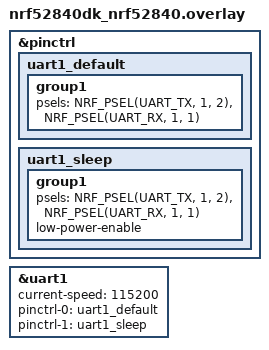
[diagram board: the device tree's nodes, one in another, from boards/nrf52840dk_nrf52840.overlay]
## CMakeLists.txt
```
cmake_minimum_required(VERSION 3.20.0)
find_package(Zephyr REQUIRED HINTS $ENV{ZEPHYR_BASE})

project(firmware)

# -----------------------------------------------------------------------------
# nanopb — generate C sources from Meshtastic .proto files
#
# firmware/proto is a symlink to the Meshtastic protobuf repo:
#   CPS-RTC/Decentralized_LoRa/nordic/proto
# (same set used by the reference project; .options files are co-located)
# -----------------------------------------------------------------------------
list(APPEND CMAKE_MODULE_PATH ${ZEPHYR_BASE}/modules/nanopb)
include(nanopb)

set(MTS_PROTO ${CMAKE_CURRENT_SOURCE_DIR}/proto)
set(NANOPB_IMPORT_DIRS ${MTS_PROTO})
set(NANOPB_GENERATE_CPP_STANDALONE OFF)

nanopb_generate_cpp(proto_srcs proto_hdrs RELPATH ${MTS_PROTO}
    ${MTS_PROTO}/meshtastic/mesh.proto
    ${MTS_PROTO}/meshtastic/portnums.proto
    ${MTS_PROTO}/meshtastic/channel.proto
    ${MTS_PROTO}/meshtastic/config.proto
    ${MTS_PROTO}/meshtastic/device_ui.proto
    ${MTS_PROTO}/meshtastic/module_config.proto
    ${MTS_PROTO}/meshtastic/atak.proto
    ${MTS_PROTO}/meshtastic/telemetry.proto
    ${MTS_PROTO}/meshtastic/xmodem.proto
)

# -----------------------------------------------------------------------------
# Application sources
# -----------------------------------------------------------------------------
target_sources(app PRIVATE
    ${proto_srcs}
    ${proto_hdrs}
    src/main.c
    src/ble_gatt.c
    src/uart_meshtastic.c
    src/proto_handler.c
    src/router.c
    src/proxy_protocol.c
    src/config_cache.c
    src/upstream_session.c
)

# nanopb generates headers into the build directory
target_include_directories(app PRIVATE ${CMAKE_CURRENT_BINARY_DIR})
```

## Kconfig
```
# =============================================================================
# Meshtastic BLE Proxy — application Kconfig
#
# Providing an app-level Kconfig makes this file the Kconfig *root* for the
# build, so it MUST source the Zephyr Kconfig tree at the end (otherwise all
# CONFIG_BT_*, CONFIG_LOG_*, etc. disappear).
# =============================================================================

menu "Meshtastic BLE Proxy"

config MESHTASTIC_ROUTE_TRACE
	bool "Enable ROUTE message-path tracing logs"
	default n
	help
	  Emit per-hop "ROUTE UP/DN ..." INFO logs that trace a message across
	  the proxy (BLE <-> UART): the phone write, the routing decision, the
	  UART TX/RX, and the per-phone serve. Useful for debugging the
	  end-to-end path during bring-up and testing.

	  This adds processing time on the packet hot path. When disabled, the
	  trace calls compile out entirely (zero overhead) — leave it off for
	  production builds and enable it only while debugging.

config MESHTASTIC_ROUTE_TRACE_PAYLOAD
	bool "Also hexdump packet payloads in ROUTE traces"
	depends on MESHTASTIC_ROUTE_TRACE
	default n
	help
	  In addition to the ROUTE path logs, hexdump the raw ToRadio bytes
	  (uplink) and the decoded FromRadio Data.payload (downlink). The
	  hexdump's ASCII column reveals text-message content. More verbose and
	  slower — enable only when you need to see the actual message bytes.

endmenu

source "Kconfig.zephyr"
```

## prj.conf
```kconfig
# =============================================================================
# Meshtastic BLE Proxy — nRF52840
# =============================================================================

# -----------------------------------------------------------------------------
# Bluetooth — Peripheral, up to 6 simultaneous connections
# -----------------------------------------------------------------------------
CONFIG_BT=y
CONFIG_BT_PERIPHERAL=y
CONFIG_BT_MAX_CONN=6
# ACL TX buffer pool: at least one per connection to avoid head-of-line blocking
CONFIG_BT_BUF_ACL_TX_COUNT=8

# -----------------------------------------------------------------------------
# Connection parameters — wide range so Android's param update is accepted
# Android sends LL_CONNECTION_PARAM_REQ at ~1-3s; if outside preferred range
# Zephyr rejects it and Android disconnects with 0x13.
# Units: 1.25 ms per interval unit, 10 ms per timeout unit.
# -----------------------------------------------------------------------------
CONFIG_BT_PERIPHERAL_PREF_MIN_INT=6
CONFIG_BT_PERIPHERAL_PREF_MAX_INT=100
CONFIG_BT_PERIPHERAL_PREF_LATENCY=0
CONFIG_BT_PERIPHERAL_PREF_TIMEOUT=400
# Must match BLE_NAME_PATTERN: ^.*_([0-9a-fA-F]{4})$
# Last 4 chars = hex suffix (ideally derived from MAC). Change before flashing.
CONFIG_BT_DEVICE_NAME="Meshtastic_CA1E"

# -----------------------------------------------------------------------------
# nanopb — protobuf decode for FromRadio routing (Phase 3)
# -----------------------------------------------------------------------------
CONFIG_NANOPB=y
CONFIG_RING_BUFFER=y

# ATT: larger MTU so FromRadio packets fit in a single read (no long-read needed)
CONFIG_BT_L2CAP_TX_MTU=251
CONFIG_BT_BUF_ACL_RX_SIZE=256
CONFIG_BT_BUF_ACL_TX_SIZE=256

# Static GATT table (BT_GATT_SERVICE_DEFINE)
CONFIG_BT_GATT_DYNAMIC_DB=n

# SMP: allow Android "Just Works" bonding.
# Android always sends Pairing Request with auth_req bonding flag set.
# CONFIG_BT_BONDABLE=n causes Zephyr to respond with bonding=0, which
# Android rejects after 3s (0x13). Allowing bonding with MAX_PAIRED=6
# lets Android complete the SC pairing and stay connected.
# Bonds are RAM-only (no CONFIG_BT_SETTINGS) — lost on reboot, which is
# fine: Android re-pairs on next connect with "Just Works".
CONFIG_BT_SMP=y
CONFIG_BT_MAX_PAIRED=6
CONFIG_BT_SMP_SC_ONLY=n
CONFIG_BT_SMP_SC_PAIR_ONLY=n

# -----------------------------------------------------------------------------
# GPIO — blinky activity LEDs (BLE read/write events)
# -----------------------------------------------------------------------------
CONFIG_GPIO=y

# -----------------------------------------------------------------------------
# UART — Meshtastic serial link on UART1 (P1.01 RX / P1.02 TX)
# -----------------------------------------------------------------------------
CONFIG_SERIAL=y
CONFIG_UART_ASYNC_API=y
# Hardware-async RX: a dedicated TIMER (via PPI) counts received bytes so the
# async driver can flush a PARTIAL DMA buffer on the UART_RX_TIMEOUT_US idle
# gap — not only when the 256-byte buffer fills. Without this, a lone FromRadio
# frame stalled in the DMA buffer until unrelated later traffic topped it up,
# coupling inbound delivery to outbound sends. TIMER0 is owned by the BLE
# controller; TIMER2 is free.
CONFIG_UART_1_NRF_HW_ASYNC=y
CONFIG_UART_1_NRF_HW_ASYNC_TIMER=2

# -----------------------------------------------------------------------------
# Logging (UART0 / JLink — independent of Meshtastic UART1)
# -----------------------------------------------------------------------------
CONFIG_LOG=y
CONFIG_LOG_DEFAULT_LEVEL=3
# Larger log buffer: the bonding/config phase bursts a lot of log traffic; a
# small buffer makes the log core drop its own lines ("--- N messages dropped ---").
CONFIG_LOG_BUFFER_SIZE=8192

# BT stack debug was only needed while chasing the 0x13 disconnect, which is now
# resolved (stable multi-phone connections). Removed: the DBG flood overran the
# log backend during bonding and caused dropped log lines. Re-enable temporarily
# if a new connection-layer issue needs tracing.
#   CONFIG_BT_CONN_LOG_LEVEL_DBG=y
#   CONFIG_BT_SMP_LOG_LEVEL_DBG=y

# -----------------------------------------------------------------------------
# Route tracing (debug) — per-hop "ROUTE UP/DN ..." logs of the message path.
# Master switch: compiles the trace calls out entirely when =n (zero overhead).
# _PAYLOAD additionally hexdumps ToRadio/FromRadio payloads (ASCII column shows
# text-message content). Turn both off for production builds.
# -----------------------------------------------------------------------------
CONFIG_MESHTASTIC_ROUTE_TRACE=y
CONFIG_MESHTASTIC_ROUTE_TRACE_PAYLOAD=y

# -----------------------------------------------------------------------------
# Memory
# -----------------------------------------------------------------------------
CONFIG_HEAP_MEM_POOL_SIZE=8192
CONFIG_MAIN_STACK_SIZE=4096
CONFIG_SYSTEM_WORKQUEUE_STACK_SIZE=2048
```

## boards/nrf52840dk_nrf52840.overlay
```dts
/*
 * Board overlay — nRF52840 DK
 *
 * UART1: Meshtastic serial link
 *   P1.02 → TX (to Meshtastic RX)
 *   P1.01 → RX (from Meshtastic TX)
 *
 * UART0 (P0.06/P0.08) stays untouched — used by Zephyr shell/logging via JLink.
 */

&pinctrl {
    uart1_default: uart1_default {
        group1 {
            psels = <NRF_PSEL(UART_TX, 1, 2)>,   /* P1.02 */
                    <NRF_PSEL(UART_RX, 1, 1)>;    /* P1.01 */
        };
    };

    uart1_sleep: uart1_sleep {
        group1 {
            psels = <NRF_PSEL(UART_TX, 1, 2)>,
                    <NRF_PSEL(UART_RX, 1, 1)>;
            low-power-enable;
        };
    };
};

&uart1 {
    status = "okay";
    current-speed = <115200>;
    pinctrl-0 = <&uart1_default>;
    pinctrl-1 = <&uart1_sleep>;
    pinctrl-names = "default", "sleep";
};
```

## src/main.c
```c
#include <zephyr/kernel.h>
#include <zephyr/bluetooth/bluetooth.h>
#include <zephyr/logging/log.h>
#include <zephyr/sys/byteorder.h>
#include <inttypes.h>
#include "ble_gatt.h"
#include "uart_meshtastic.h"
#include "proto_handler.h"
#include "router.h"
#include "upstream_session.h"
#include "proxy_protocol.h"
#include "route_trace.h"

LOG_MODULE_REGISTER(main, LOG_LEVEL_INF);

/*
 * Called (system work-queue context) when the UART driver has assembled a
 * complete FromRadio frame from the Meshtastic node.
 *
 * Flow:
 *   1. Decode the protobuf (nanopb) to extract routing fields.
 *   2. Dispatch raw bytes to the correct BLE connection(s) via the router.
 *
 * On decode failure the raw bytes are still broadcast so no packet is dropped.
 */
static void on_fromradio_uart(const uint8_t *payload, uint16_t len)
{
    struct fromradio_info info;

    if (proto_decode_fromradio(payload, len, &info) != 0) {
        /* Decode failed (malformed frame?). Broadcast raw as fallback. */
        LOG_WRN("FromRadio decode failed — broadcasting raw (%d B)", len);
        ble_gatt_broadcast_fromradio(payload, len);
        return;
    }

    router_dispatch(payload, len, &info);
}

/*
 * Called when a phone writes a ToRadio protobuf to the GATT TORADIO
 * characteristic (per-phone config-session virtualization).
 *
 * The proxy is NO LONGER a blind passthrough:
 *   - want_config_id : served LOCALLY from the cache (replay or PENDING).
 *                      NEVER forwarded to UART — forwarding it would restart the
 *                      node's single global config session and clobber every
 *                      other phone's in-flight handshake.
 *   - heartbeat      : absorbed locally — answered with a synthesized
 *                      queueStatus for liveness; NEVER forwarded to UART. The
 *                      node's serial link is kept alive by the proxy's own
 *                      keepalive, and delivery of inbound FromRadio is driven by
 *                      the node's push (not by client ToRadio), so forwarding
 *                      heartbeats is unnecessary.
 *   - anything else  : a real packet → forwarded to the node via UART as today.
 *
 * On decode failure we forward the raw bytes best-effort (no silent drop).
 */
static void on_toradio_ble(struct bt_conn *conn, const uint8_t *data, uint16_t len)
{
    struct toradio_info ti;

    if (proto_decode_toradio(data, len, &ti) != 0) {
        /* Malformed ToRadio — forward best-effort so nothing is silently lost. */
        LOG_WRN("ToRadio decode failed (%d B) from conn %p — forwarding raw",
                len, (void *)conn);
        (void)uart_meshtastic_tx(data, len);
        return;
    }

    if (ti.has_want_config) {
        /* Serve config locally: replay if the cache is ready, else PENDING. */
        enum upstream_state st = upstream_get_state();
        if (st == UPSTREAM_CACHE_READY || st == UPSTREAM_LIVE) {
            LOG_INF("want_config nonce=%u from conn %p → replay cached burst",
                    (unsigned)ti.want_config_id, (void *)conn);
            ble_gatt_replay_cached_burst(conn, ti.want_config_id);
        } else {
            LOG_INF("want_config nonce=%u from conn %p → PENDING (cache not ready)",
                    (unsigned)ti.want_config_id, (void *)conn);
            ble_gatt_park_pending(conn, ti.want_config_id);
        }
        return;  /* NEVER forward want_config to UART. */
    }

    if (ti.has_heartbeat) {
        /* Absorbed locally: reply a synthesized queueStatus to keep the
         * phone's liveness timer alive. */
        ble_gatt_reply_queuestatus(conn);
        return;
    }
#if IS_ENABLED(CONFIG_MESHTASTIC_ROUTE_TRACE)
    /* TESTING ONLY: Assumes proxy-framed payload with 4-byte IDs. */
    if (ti.is_packet && ti.portnum == PROXY_PORTNUM && ti.payload_len >= PROXY_HEADER_SIZE) {
        ROUTE_TRACE("ROUTE UP  hdr=[%02x][0x%08" PRIx32 "][0x%08" PRIx32 "] content='%.*s'",
                    ti.payload_bytes[PROXY_OFF_VERSION],
                    sys_get_be32(&ti.payload_bytes[PROXY_OFF_SRC]),
                    sys_get_be32(&ti.payload_bytes[PROXY_OFF_DST]),
                    (int)(ti.payload_len - PROXY_HEADER_SIZE),
                    (const char *)&ti.payload_bytes[PROXY_OFF_CONTENT]);
        ROUTE_TRACE_HEXDUMP(ti.payload_bytes, ti.payload_len, "ROUTE UP payload");
    }
#endif 
    /* Real packet → forward to the node, and push the upstream keepalive out
     * the keepalive only fires after a stretch of true silence. */
    int err = uart_meshtastic_tx(data, len);
    if (err == -ENOMEM) {
        LOG_WRN("TX queue full — ToRadio from conn %p dropped", (void *)conn);
    } else if (err) {
        LOG_ERR("uart_meshtastic_tx: %d", err);
    } else {
        upstream_keepalive_reschedule();
    }
}

int main(void)
{
    int err;

    LOG_INF("=== Meshtastic BLE Proxy starting ===");

    /* 1. Init GATT service (must happen before bt_enable). */
    err = ble_gatt_init(on_toradio_ble);
    if (err) {
        LOG_ERR("ble_gatt_init: %d", err);
        return err;
    }

    /* 2. Enable Bluetooth stack. */
    err = bt_enable(NULL);
    if (err) {
        LOG_ERR("bt_enable: %d", err);
        return err;
    }
    LOG_INF("Bluetooth ready");

    /* 3. Start advertising as a Meshtastic-compatible peripheral. */
    err = ble_gatt_start_advertising();
    if (err) {
        return err;
    }

    /* 4. Init UART driver — starts DMA reception immediately.
     *    The Meshtastic node begins sending FromRadio frames once it receives
     *    the proxy's own want_config_id ToRadio (sent by upstream_session_start
     *    below), not a phone's — phones are served from the cache. */
    err = uart_meshtastic_init(on_fromradio_uart);
    if (err) {
        LOG_ERR("uart_meshtastic_init: %d", err);
        return err;
    }

    /* 5. Wire the per-phone replay callback BEFORE starting the upstream fetch,
     *    so any PENDING phone queued during FETCHING is served the instant the
     *    cache becomes ready. */
    upstream_set_serve_cb(ble_gatt_replay_cached_burst);

    /* 6. Kick off the proxy's own boot want_config: fetch the node's config
     *    burst into the cache, then go LIVE. Phones connecting before the cache
     *    is ready are parked PENDING and replayed once ready. */
    upstream_session_start();

    /* Main loop — all work runs in the system work queue and BT callbacks. */
    while (1) {
        k_sleep(K_MSEC(100));
    }

    return 0;
}
```

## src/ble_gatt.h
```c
#ifndef BLE_GATT_H
#define BLE_GATT_H

#include <stdint.h>
#include <zephyr/bluetooth/conn.h>
#include "proxy_protocol.h"

/* Max simultaneous BLE connections (phones).
 * Tied to CONFIG_BT_MAX_CONN so the app-layer slot array always matches the
 * BT stack limit. Change prj.conf (CONFIG_BT_MAX_CONN) to resize both at once. */
#define MAX_BLE_CONNECTIONS     CONFIG_BT_MAX_CONN

/* Per-connection FromRadio packet queue depth */
#define FROMRADIO_QUEUE_DEPTH   8

/* Max size of a single FromRadio protobuf packet (bytes) */
#define FROMRADIO_MAX_PKT_SIZE  512

/*
 * Per-phone config-session state.
 *
 *   CONNECTED          → just connected (CCCD not yet subscribed)
 *   AWAIT_WANT_CONFIG  → subscribed, waiting for the phone's want_config
 *   PENDING            → asked for config before the cache was ready; queued in
 *                        upstream_session and served once CACHE_READY
 *   REPLAYING          → mid burst replay (cursor walking the shared cache)
 *   ACTIVE             → burst replayed + config_complete sent; live traffic
 */
enum phone_state {
    PHONE_CONNECTED,
    PHONE_AWAIT_WANT_CONFIG,
    PHONE_PENDING,
    PHONE_REPLAYING,
    PHONE_ACTIVE,
};

/**
 * Callback fired when a connected phone writes to the TORADIO characteristic.
 *
 * @param conn  BLE connection that sent the data.
 * @param data  Raw protobuf bytes (ToRadio message, already encoded by the app).
 * @param len   Length in bytes.
 */
typedef void (*toradio_cb_t)(struct bt_conn *conn, const uint8_t *data, uint16_t len);

/** Initialize GATT service and connection tracking. Must be called before bt_enable(). */
int ble_gatt_init(toradio_cb_t cb);

/** Start BLE advertising (Meshtastic-compatible). Called at boot and after each connection. */
int ble_gatt_start_advertising(void);

/**
 * Enqueue a FromRadio packet for a specific BLE connection.
 * Triggers a FROMNUM notification to the phone.
 *
 * @return  0        success
 *         -ENOENT   connection not tracked
 *         -ENOMEM   per-connection queue full
 *         -EMSGSIZE packet exceeds FROMRADIO_MAX_PKT_SIZE
 */
int ble_gatt_enqueue_fromradio(struct bt_conn *conn, const uint8_t *data, uint16_t len);

/**
 * Enqueue a FromRadio packet for ALL currently connected BLE clients.
 * Used for config/meta variants and broadcast mesh packets.
 *
 * @return Number of connections that received the packet (0 if none connected).
 */
int ble_gatt_broadcast_fromradio(const uint8_t *data, uint16_t len);

/**
 * Return the BLE connection whose registered proxy_id matches the given id.
 * Returns NULL if no connection has registered that id.
 *
 * Used by the router to target a specific phone by its proxy identifier.
 */
struct bt_conn *ble_gatt_get_conn_by_proxy_id(const proxy_id_t *id);

/**
 * Register a proxy identifier (phone number, UUID, etc.) for a BLE connection.
 *
 * Called from the NODE_REG GATT write handler when a phone writes its 16-byte
 * identifier.  The router uses this mapping to perform targeted delivery.
 *
 * @param conn  The BLE connection registering.
 * @param id    16-byte proxy identifier written by the phone.
 * @return 0 on success, -ENOENT if connection is not tracked.
 */
int ble_gatt_register_proxy_id(struct bt_conn *conn, const proxy_id_t *id);

/*
 * Replay the boot-populated config cache to a single phone, then close the
 * burst with a synthesized FromRadio{config_complete_id = nonce} carrying THAT
 * phone's nonce (per-phone replay).
 *
 * Frames are read straight from the shared config_cache arena via a cursor and
 * enqueued one by one — the whole burst is never copied into the per-conn queue
 * as a block (avoids N× RAM duplication). On completion the phone goes ACTIVE.
 *
 * Called from on_toradio_ble (cache already ready) and registered with
 * upstream_session as the serve callback for PENDING phones.
 */
void ble_gatt_replay_cached_burst(struct bt_conn *conn, uint32_t nonce);

/*
 * Park a phone as PENDING: it asked for config before the cache was ready.
 * Records the phone's nonce and registers it with upstream_session, which
 * replays the burst (via the serve callback) once CACHE_READY.
 */
void ble_gatt_park_pending(struct bt_conn *conn, uint32_t nonce);

/*
 * Task D — reactive BLE liveness reply. Enqueue a synthesized FromRadio{
 * queueStatus} to this connection (bumps fromnum + notifies FROMNUM) in
 * response to the phone's ToRadio.heartbeat. The phone reads it as "radio
 * data", keeping its app-layer liveness timer from tripping. Absorbed locally
 * — the heartbeat is NEVER forwarded to UART. The queueStatus is encoded once
 * and reused.
 */
void ble_gatt_reply_queuestatus(struct bt_conn *conn);

#endif /* BLE_GATT_H */
```

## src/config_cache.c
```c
/*
 * config_cache.c — packed contiguous store of the node's config burst.
 *
 * Layout
 * ------
 *   s_arena[CONFIG_CACHE_ARENA_BYTES]   one byte buffer, frames packed
 *                                       back-to-back, NO per-frame padding.
 *   s_index[CONFIG_CACHE_MAX_FRAMES]    {offset, len, variant} per stored frame.
 *   s_used                              bytes consumed in the arena so far.
 *   s_count                             number of index entries used.
 *   s_ready (atomic_t)                  publish flag (see barrier note below).
 *   s_queuestatus_idx                   index of the cached queueStatus frame,
 *                                       or -1 if none was stored.
 *
 * Threading / memory model
 * ------------------------
 * NO mutexes. All writers (cache_begin / cache_add_frame / cache_mark_ready)
 * run on the single Zephyr system work queue (UART RX → upstream_session), so
 * they never race. Publication uses a Zephyr atomic_t:
 *
 *   - cache_mark_ready() does atomic_set(&s_ready, 1). atomic_set is a
 *     release-store: all prior plain writes (every arena byte, every s_index
 *     entry, s_used, s_count, s_queuestatus_idx) are visible to any thread
 *     that subsequently observes the new value of s_ready.
 *   - cache_is_ready() does atomic_get(&s_ready), an acquire-load: once it
 *     returns true, the reader is guaranteed to see the fully-written arena.
 *
 * This is the ONLY synchronization the cache relies on; it is correct even if a
 * future reader is moved off the system work queue (e.g. a BLE TX thread)
 * without adding a mutex. See config_cache.h for the full rationale.
 */

#include "config_cache.h"

#include <string.h>
#include <errno.h>
#include <zephyr/sys/atomic.h>
#include <zephyr/logging/log.h>

#include "meshtastic/mesh.pb.h"   /* meshtastic_FromRadio_queueStatus_tag */

LOG_MODULE_REGISTER(config_cache, LOG_LEVEL_INF);

static uint8_t                s_arena[CONFIG_CACHE_ARENA_BYTES];
static struct cache_frame_ref s_index[CONFIG_CACHE_MAX_FRAMES];
static uint16_t               s_used;
static uint16_t               s_count;
static atomic_t               s_ready;
static int                    s_queuestatus_idx = -1;
static int                    s_own_nodeinfo_idx = -1;  /* first node_info = OWN */

void cache_begin(void)
{
    /* Reset for a fresh burst. Clear ready FIRST so no reader can observe a
     * stale "ready" while we are mid-rewrite. */
    atomic_set(&s_ready, 0);
    s_used             = 0;
    s_count            = 0;
    s_queuestatus_idx  = -1;
    s_own_nodeinfo_idx = -1;
    LOG_INF("cache_begin: arena=%u B, max_frames=%u",
            (unsigned)CONFIG_CACHE_ARENA_BYTES,
            (unsigned)CONFIG_CACHE_MAX_FRAMES);
}

int cache_add_frame(const uint8_t *raw, uint16_t len, int variant)
{
    /* Overflow policy: never silently cap. Reject the frame and
     * LOG_WRN with exact byte counts; the fixed part + first K node_info that
     * already fit remain valid, the rest repopulate via live broadcast. */
    if (s_count >= CONFIG_CACHE_MAX_FRAMES) {
        LOG_WRN("frame cap reached: %u/%u frames, dropping variant=%d (%u B); "
                "remaining frames repopulate via live broadcast",
                (unsigned)s_count, (unsigned)CONFIG_CACHE_MAX_FRAMES,
                variant, (unsigned)len);
        return -ENOMEM;
    }

    if ((uint32_t)s_used + (uint32_t)len > CONFIG_CACHE_ARENA_BYTES) {
        LOG_WRN("arena overflow: used=%u B + frame=%u B > arena=%u B, "
                "dropping variant=%d; remaining frames repopulate via live "
                "broadcast",
                (unsigned)s_used, (unsigned)len,
                (unsigned)CONFIG_CACHE_ARENA_BYTES, variant);
        return -ENOMEM;
    }

    memcpy(&s_arena[s_used], raw, len);
    s_index[s_count].offset  = s_used;
    s_index[s_count].len     = len;
    s_index[s_count].variant = variant;

    /* Remember the queueStatus frame for fast lookup by cache_get_queuestatus.
     * Keep the last one seen (the node emits at most one in the burst). */
    if (variant == meshtastic_FromRadio_queueStatus_tag) {
        s_queuestatus_idx = (int)s_count;
    }

    /* Remember the FIRST node_info: it is the node's OWN NodeInfo (the burst
     * always sends own node_info before the other-node node_infos). Used to
     * segment replays for the special want_config nonces. */
    if (variant == meshtastic_FromRadio_node_info_tag && s_own_nodeinfo_idx < 0) {
        s_own_nodeinfo_idx = (int)s_count;
    }

    LOG_DBG("cache_add_frame: idx=%u variant=%d len=%u (used=%u B)",
            (unsigned)s_count, variant, (unsigned)len,
            (unsigned)(s_used + len));

    s_used  += len;
    s_count += 1;
    return 0;
}

void cache_mark_ready(void)
{
    /* Release-store: publishes every preceding arena/index write. See header. */
    atomic_set(&s_ready, 1);
    LOG_INF("cache_mark_ready: %u frames, %u B published",
            (unsigned)s_count, (unsigned)s_used);
}

bool cache_is_ready(void)
{
    /* Acquire-load: pairs with the release-store in cache_mark_ready(). */
    return atomic_get(&s_ready) != 0;
}

const struct cache_frame_ref *cache_frame_at(uint16_t idx)
{
    if (idx >= s_count) {
        return NULL;
    }
    return &s_index[idx];
}

const uint8_t *cache_frame_bytes(const struct cache_frame_ref *ref)
{
    if (ref == NULL) {
        return NULL;
    }
    return &s_arena[ref->offset];
}

uint16_t cache_frame_count(void)
{
    return s_count;
}

bool cache_get_queuestatus(const uint8_t **out_buf, uint16_t *out_len)
{
    if (s_queuestatus_idx < 0) {
        return false;
    }
    const struct cache_frame_ref *ref = &s_index[s_queuestatus_idx];
    *out_buf = &s_arena[ref->offset];
    *out_len = ref->len;
    return true;
}

bool cache_frame_in_segment(uint16_t idx, uint32_t nonce)
{
    if (idx >= s_count) {
        return false;
    }

    int variant = s_index[idx].variant;

    /* config_complete_id is the terminator — synthesized per phone, never
     * replayed from the cache (would carry the boot nonce). */
    if (variant == meshtastic_FromRadio_config_complete_id_tag) {
        return false;
    }

    bool is_nodeinfo = (variant == meshtastic_FromRadio_node_info_tag);

    if (nonce == MESH_NONCE_ONLY_NODES) {
        /* ONLY_NODES (69421): node_info frames only (own + others). */
        return is_nodeinfo;
    }

    if (nonce == MESH_NONCE_ONLY_CONFIG) {
        /* ONLY_CONFIG (69420): everything except other-node node_info; keep the
         * OWN node_info (the first one). */
        if (is_nodeinfo && (int)idx != s_own_nodeinfo_idx) {
            return false;
        }
        return true;
    }

    /* Normal nonce: replay the full burst. */
    return true;
}
```

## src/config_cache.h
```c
#ifndef CONFIG_CACHE_H
#define CONFIG_CACHE_H

#include <stdint.h>
#include <stdbool.h>

/*
 * config_cache — boot-populated, read-only-after-ready store of the node's
 * config burst (the ordered FromRadio frames the node emits in response to a
 * want_config).
 *
 * The arena is a single packed contiguous byte buffer: frames are stored
 * back-to-back with NO per-frame padding (the per-frame 512 B cap is a
 * transport limit, not a storage layout). An index array of
 * {offset, len, variant} records where each frame lives.
 *
 * Lifecycle (driven by upstream_session):
 *   cache_begin()                  reset arena + index (UPSTREAM_FETCHING start)
 *   cache_add_frame(raw,len,var)   append one FromRadio frame, in burst order
 *   cache_mark_ready()             publish: arena is now immutable
 *   cache_is_ready()               readers gate on this before touching frames
 *   cache_frame_at(idx)/count()    iterate frames for per-phone replay
 *   cache_get_queuestatus()        fetch the cached queueStatus frame, if any
 *
 * Threading / memory model
 * ------------------------
 * There are NO mutexes in this module. All writes (cache_begin / cache_add_frame
 * / cache_mark_ready) run on the single Zephyr system work queue (the UART RX
 * callback path), so writers never race each other. Readers (per-phone replay
 * in ble_gatt) also run on the system work queue today — but
 * cache_mark_ready() still publishes via a Zephyr atomic_t store, and
 * cache_is_ready() reads it via an atomic load. Those atomics carry the
 * acquire/release barrier that guarantees: any reader that observes
 * cache_is_ready() == true also observes every byte written into the arena and
 * every index entry before cache_mark_ready() was called. This makes the cache
 * correct even if a future reader is moved to another context (e.g. a BLE TX
 * thread) without adding a mutex.
 */

/* Default arena size — 4 KB. RAM budget sizes this from the real
 * node's Phase 0 boot measurement; upstream_session logs the observed total.
 * Update this define once Phase 0 has been measured. */
#define CONFIG_CACHE_ARENA_BYTES 4096  /* 4 KB default; update after Phase 0 measurement */

/* Max number of frames the index can hold. node_info dominates the count
 * (one frame per mesh node). */
#define CONFIG_CACHE_MAX_FRAMES 128

/*
 * One index entry. variant is the meshtastic_FromRadio_*_tag of the frame.
 * raw bytes live at &arena[offset], length len. Read-only after ready.
 */
struct cache_frame_ref {
    uint16_t offset;   /* byte offset into the arena                 */
    uint16_t len;      /* frame length in bytes                       */
    int      variant;  /* meshtastic_FromRadio_*_tag                  */
};

/* Reset the cache for a fresh burst. Clears arena cursor, index and the
 * ready flag. Call at the start of UPSTREAM_FETCHING. */
void cache_begin(void);

/*
 * Append one raw FromRadio frame (protobuf bytes, no serial header) to the
 * arena, in burst order.
 *
 * Overflow policy: if appending this frame
 * would exceed CONFIG_CACHE_ARENA_BYTES or CONFIG_CACHE_MAX_FRAMES, the frame
 * is rejected and a LOG_WRN is emitted with exact byte counts. The fixed part
 * of the burst (my_info, deviceuiConfig, metadata, channel, config,
 * moduleConfig, fileInfo) plus the first K node_info frames that DID fit are
 * kept; later node_info frames repopulate via live broadcast. The rejected
 * frame is simply not stored.
 *
 * @return 0 on success, -ENOMEM if the frame did not fit (arena or frame cap).
 */
int cache_add_frame(const uint8_t *raw, uint16_t len, int variant);

/* Publish the cache: store the ready flag with release semantics so any reader
 * that sees cache_is_ready() observes the fully-written arena. */
void cache_mark_ready(void);

/* True once cache_mark_ready() has been called (acquire load). */
bool cache_is_ready(void);

/* Return the index entry for frame idx, or NULL if idx is out of range. */
const struct cache_frame_ref *cache_frame_at(uint16_t idx);

/*
 * Return a read-only pointer to the raw bytes of the frame described by ref.
 *
 * The arena is private to config_cache; per-phone replay (ble_gatt) holds only
 * a cache_frame_ref (from cache_frame_at) and resolves it to bytes here, so the
 * replay path reads STRAIGHT FROM THE SHARED ARENA — no per-connection copy of
 * the burst. The pointer is valid for the cache lifetime
 * (read-only after cache_mark_ready). Returns NULL if ref is NULL.
 */
const uint8_t *cache_frame_bytes(const struct cache_frame_ref *ref);

/* Number of frames currently stored. */
uint16_t cache_frame_count(void);

/*
 * Meshtastic special want_config nonces (PhoneAPI). The real phone app fetches
 * the node in TWO rounds with these sentinel nonces (confirmed against a real
 * node, .tmp/burst_*.hex, and NimbleBluetooth.cpp). See memory
 * meshtastic-want-config-special-nonces.
 */
#define MESH_NONCE_ONLY_CONFIG 69420u  /* config + OWN node_info; skip other nodes */
#define MESH_NONCE_ONLY_NODES  69421u  /* node_info only (own + others)            */

/*
 * Whether cached frame `idx` should be replayed for a phone that sent `nonce`.
 *
 *   MESH_NONCE_ONLY_NODES (69421): only node_info frames.
 *   MESH_NONCE_ONLY_CONFIG (69420): everything EXCEPT non-first node_info
 *       (keep the OWN node_info — the first one — drop other-node node_info).
 *   any other nonce: the full burst (true for every frame).
 *
 * A config_complete_id frame is NEVER served from the cache (the replay
 * synthesizes it per phone), so this returns false for that variant in all
 * segments. Returns false for out-of-range idx.
 */
bool cache_frame_in_segment(uint16_t idx, uint32_t nonce);

/*
 * Fetch the cached queueStatus frame (variant
 * meshtastic_FromRadio_queueStatus_tag) for BLE liveness replies.
 *
 * @param out_buf  on success, receives a pointer into the arena.
 * @param out_len  on success, receives the frame length.
 * @return true if a queueStatus frame was cached, false otherwise.
 */
bool cache_get_queuestatus(const uint8_t **out_buf, uint16_t *out_len);

#endif /* CONFIG_CACHE_H */
```

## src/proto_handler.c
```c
/*
 * proto_handler.c — nanopb decode of Meshtastic FromRadio messages
 *
 * Extracts the fields needed for routing:
 *   - which_payload_variant
 *   - packet.from / packet.to
 *   - packet.decoded.portnum
 *   - packet.decoded.payload.bytes / .size
 *
 * The node decrypts packets before sending over serial, so
 * MeshPacket.which_payload_variant == decoded_tag for all
 * application-layer traffic (see Meshtastic StreamAPI docs).
 *
 * FromRadio raw bytes are NOT re-encoded — forwarded as-is to BLE by the
 * router. The only message the proxy synthesizes (encodes) is the closing
 * FromRadio{config_complete_id} of the per-phone replay; that is built with
 * nanopb pb_encode (never hand-written wire bytes).
 *
 * Threading: every decode/encode entry point uses a module-level static
 * scratch struct (too large for any stack). This is safe ONLY because all
 * decode/cache processing runs on the single Zephyr system work queue —
 * there is no concurrent caller. Do NOT call these from an ISR or a second
 * thread.
 */

#include "proto_handler.h"

#include <string.h>
#include <errno.h>
#include <pb_decode.h>
#include <pb_encode.h>
#include "meshtastic/mesh.pb.h"
#include <zephyr/logging/log.h>

LOG_MODULE_REGISTER(proto_handler, LOG_LEVEL_DBG);

/*
 * Module-level statics: each too large (~2 KB) for any stack. Kept separate
 * (FromRadio vs ToRadio) so a ToRadio decode never clobbers a FromRadio
 * decode in flight. Safe because the single system work queue serializes all
 * access — see the threading note in the file header.
 */
static meshtastic_FromRadio s_fromradio;
static meshtastic_ToRadio   s_toradio;

int proto_decode_fromradio(const uint8_t *buf, uint16_t len,
                           struct fromradio_info *out)
{
    memset(&s_fromradio, 0, sizeof(s_fromradio));
    memset(out, 0, sizeof(*out));

    pb_istream_t stream = pb_istream_from_buffer(buf, len);
    if (!pb_decode(&stream, meshtastic_FromRadio_fields, &s_fromradio)) {
        LOG_WRN("pb_decode: %s", PB_GET_ERROR(&stream));
        return -EINVAL;
    }

    out->which_variant = s_fromradio.which_payload_variant;

    if (s_fromradio.which_payload_variant != meshtastic_FromRadio_packet_tag) {
        /* Config, NodeInfo, MyInfo, Channel, ConfigComplete, etc. */
        LOG_DBG("variant=%d (config/meta)", out->which_variant);
        return 0;
    }

    /* It's a MeshPacket — extract routing fields. */
    out->packet_from = s_fromradio.packet.from;
    out->packet_to   = s_fromradio.packet.to;

    if (s_fromradio.packet.which_payload_variant !=
        meshtastic_MeshPacket_decoded_tag) {
        /* Encrypted packet — cannot inspect payload. */
        out->is_decoded = false;
        LOG_DBG("packet from=0x%08x to=0x%08x (encrypted)",
                out->packet_from, out->packet_to);
        return 0;
    }

    /* Decoded (plaintext) packet — expose portnum + payload. */
    out->is_decoded    = true;
    out->portnum       = s_fromradio.packet.decoded.portnum;
    out->payload_bytes = s_fromradio.packet.decoded.payload.bytes;
    out->payload_len   = (uint16_t)s_fromradio.packet.decoded.payload.size;

    LOG_DBG("packet from=0x%08x to=0x%08x portnum=%u payload=%u B",
            out->packet_from, out->packet_to,
            out->portnum, out->payload_len);

    return 0;
}

int proto_decode_toradio(const uint8_t *buf, uint16_t len,
                         struct toradio_info *out)
{
    /* See file header: s_toradio is reused per call — single-threaded only. */
    memset(&s_toradio, 0, sizeof(s_toradio));
    memset(out, 0, sizeof(*out));

    pb_istream_t stream = pb_istream_from_buffer(buf, len);
    if (!pb_decode(&stream, meshtastic_ToRadio_fields, &s_toradio)) {
        LOG_WRN("ToRadio pb_decode: %s", PB_GET_ERROR(&stream));
        return -EINVAL;
    }

    switch (s_toradio.which_payload_variant) {
    case meshtastic_ToRadio_want_config_id_tag:
        out->has_want_config = true;
        out->want_config_id  = s_toradio.want_config_id;
        LOG_DBG("ToRadio want_config_id=%u", out->want_config_id);
        break;
    case meshtastic_ToRadio_heartbeat_tag:
        out->has_heartbeat = true;
        LOG_DBG("ToRadio heartbeat");
        break;
    default:
        /* packet / disconnect / xmodem / mqtt / empty — caller forwards. */
        if (s_toradio.which_payload_variant == meshtastic_ToRadio_packet_tag &&
            s_toradio.packet.which_payload_variant ==
                meshtastic_MeshPacket_decoded_tag) {
            /* Decoded phone->radio packet: expose portnum + payload so the
             * forward path can trace the proxy wire header. Bytes are still
             * forwarded verbatim by the caller. */
            out->is_packet     = true;
            out->portnum       = s_toradio.packet.decoded.portnum;
            out->payload_bytes = s_toradio.packet.decoded.payload.bytes;
            out->payload_len   = (uint16_t)s_toradio.packet.decoded.payload.size;
        }
        LOG_DBG("ToRadio variant=%d (passthrough)",
                s_toradio.which_payload_variant);
        break;
    }

    return 0;
}

int proto_encode_config_complete(uint32_t nonce, uint8_t *out_buf,
                                 uint16_t buf_size, uint16_t *out_len)
{
    /* Build the FromRadio entirely via nanopb — no hand-written wire bytes. */
    meshtastic_FromRadio fr = meshtastic_FromRadio_init_zero;
    fr.which_payload_variant = meshtastic_FromRadio_config_complete_id_tag;
    fr.config_complete_id    = nonce;

    pb_ostream_t stream = pb_ostream_from_buffer(out_buf, buf_size);
    if (!pb_encode(&stream, meshtastic_FromRadio_fields, &fr)) {
        /* nanopb reports a buffer-too-small condition here as well; map it to
         * -ENOMEM so callers can distinguish it from a structural failure. */
        if (stream.bytes_written >= buf_size) {
            LOG_WRN("config_complete encode: buffer too small (%u B)",
                    buf_size);
            return -ENOMEM;
        }
        LOG_WRN("config_complete pb_encode: %s", PB_GET_ERROR(&stream));
        return -EINVAL;
    }

    *out_len = (uint16_t)stream.bytes_written;
    LOG_DBG("config_complete encoded nonce=%u -> %u B", nonce, *out_len);

    return 0;
}

int proto_encode_heartbeat(uint32_t nonce, uint8_t *out_buf,
                           uint16_t buf_size, uint16_t *out_len)
{
    /* ToRadio{ heartbeat = { nonce } } via nanopb — no hand-written bytes. */
    meshtastic_ToRadio tr = meshtastic_ToRadio_init_zero;
    tr.which_payload_variant = meshtastic_ToRadio_heartbeat_tag;
    tr.heartbeat.nonce       = nonce;

    pb_ostream_t stream = pb_ostream_from_buffer(out_buf, buf_size);
    if (!pb_encode(&stream, meshtastic_ToRadio_fields, &tr)) {
        if (stream.bytes_written >= buf_size) {
            LOG_WRN("heartbeat encode: buffer too small (%u B)", buf_size);
            return -ENOMEM;
        }
        LOG_WRN("heartbeat pb_encode: %s", PB_GET_ERROR(&stream));
        return -EINVAL;
    }

    *out_len = (uint16_t)stream.bytes_written;
    LOG_DBG("heartbeat encoded nonce=%u -> %u B", nonce, *out_len);

    return 0;
}

int proto_encode_queue_status(uint8_t *out_buf, uint16_t buf_size,
                              uint16_t *out_len)
{
    /* FromRadio{ queueStatus } via nanopb. Benign, well-formed values: success
     * (res=0), some free/maxlen capacity, no specific mesh_packet_id. Only used
     * for BLE heartbeat liveness — the phone just needs valid radio data. */
    meshtastic_FromRadio fr = meshtastic_FromRadio_init_zero;
    fr.which_payload_variant      = meshtastic_FromRadio_queueStatus_tag;
    fr.queueStatus.res            = 0;
    fr.queueStatus.free           = 16;
    fr.queueStatus.maxlen         = 16;
    fr.queueStatus.mesh_packet_id = 0;

    pb_ostream_t stream = pb_ostream_from_buffer(out_buf, buf_size);
    if (!pb_encode(&stream, meshtastic_FromRadio_fields, &fr)) {
        if (stream.bytes_written >= buf_size) {
            LOG_WRN("queueStatus encode: buffer too small (%u B)", buf_size);
            return -ENOMEM;
        }
        LOG_WRN("queueStatus pb_encode: %s", PB_GET_ERROR(&stream));
        return -EINVAL;
    }

    *out_len = (uint16_t)stream.bytes_written;
    LOG_DBG("queueStatus encoded -> %u B", *out_len);

    return 0;
}
```

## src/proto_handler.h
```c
#ifndef PROTO_HANDLER_H
#define PROTO_HANDLER_H

#include <stdint.h>
#include <stdbool.h>

/*
 * Routing information extracted from a decoded FromRadio message.
 *
 * payload_bytes / payload_len are valid only when:
 *   which_variant==meshtastic_FromRadio_packet_tag AND is_decoded==true
 *
 * payload_bytes points into proto_handler's internal static buffer.
 * It remains valid until the next call to proto_decode_fromradio().
 * Since all processing is single-threaded (system work queue), this is safe.
 */
struct fromradio_info {
    int       which_variant;    /* meshtastic_FromRadio_*_tag             */
    uint32_t  packet_from;      /* MeshPacket.from                        */
    uint32_t  packet_to;        /* MeshPacket.to                          */
    bool      is_decoded;       /* MeshPacket variant == decoded (not encrypted) */
    uint32_t  portnum;          /* Data.portnum  — valid when is_decoded   */
    const uint8_t *payload_bytes; /* Data.payload.bytes — valid when is_decoded */
    uint16_t  payload_len;      /* Data.payload.size  — valid when is_decoded */
};

/*
 * Decode raw FromRadio protobuf bytes and populate routing fields.
 *
 * Uses a module-level static for the decoded struct (~2 KB) — must not be
 * called concurrently from multiple threads.
 *
 * @return 0 on success, -EINVAL on nanopb decode failure.
 */
int proto_decode_fromradio(const uint8_t *buf, uint16_t len,
                           struct fromradio_info *out);

/*
 * Information extracted from a decoded ToRadio message (phone -> radio).
 *
 * The proxy only cares about two control variants on the BLE write path:
 *   - want_config_id : the phone is requesting the config burst; the proxy
 *                      serves this locally from the cache (never forwards to
 *                      UART). The nonce is echoed back in config_complete_id.
 *   - heartbeat      : serial-link keepalive; absorbed locally (reactive
 *                      queueStatus reply), never forwarded to UART.
 *
 * Any other variant (notably `packet`) leaves both has_* flags false and is
 * forwarded to UART as today.
 */
struct toradio_info {
    bool      has_want_config;  /* which_payload_variant == want_config_id_tag */
    uint32_t  want_config_id;   /* the phone's config nonce — valid iff above  */
    bool      has_heartbeat;    /* which_payload_variant == heartbeat_tag      */

    /* Decoded MeshPacket payload (phone -> radio real packet). Valid only when
     * is_packet == true; payload_bytes points into proto_handler's internal
     * static buffer (valid until the next proto_decode_toradio call). Exposed
     * so the forward path can inspect the proxy header for tracing without
     * re-decoding — the bytes are still forwarded to UART verbatim. */
    bool      is_packet;        /* packet variant AND decoded (not encrypted)  */
    uint32_t  portnum;          /* Data.portnum — valid when is_packet          */
    const uint8_t *payload_bytes; /* Data.payload.bytes — valid when is_packet */
    uint16_t  payload_len;      /* Data.payload.size  — valid when is_packet    */
};

/*
 * Decode raw ToRadio protobuf bytes (phone -> radio) and populate out.
 *
 * Uses a module-level static for the decoded struct (~2 KB) — separate from
 * the FromRadio static — must not be called concurrently from multiple
 * threads. Safe here because all decode/cache processing runs on the single
 * system work queue (see proto_handler.c).
 *
 * @return 0 on success, -EINVAL on nanopb decode failure.
 */
int proto_decode_toradio(const uint8_t *buf, uint16_t len,
                         struct toradio_info *out);

/*
 * Encode a synthetic FromRadio{config_complete_id = nonce} into out_buf.
 *
 * Used by the per-phone replay path to close a phone's config burst with
 * that phone's own nonce. The message is built with nanopb pb_encode against
 * meshtastic_FromRadio_fields — never hand-written tag/varint bytes.
 *
 * @param nonce     the phone's want_config nonce to echo back.
 * @param out_buf   destination buffer.
 * @param buf_size  size of out_buf in bytes.
 * @param out_len   on success, receives the number of bytes written.
 * @return 0 on success, -ENOMEM if out_buf is too small, -EINVAL on encode
 *         failure.
 */
int proto_encode_config_complete(uint32_t nonce, uint8_t *out_buf,
                                 uint16_t buf_size, uint16_t *out_len);

/*
 * Encode a ToRadio{heartbeat = {nonce}} into out_buf (Task D — upstream UART
 * keepalive). The proxy sends this to the node to refresh the node's serial
 * activity timer (15-min timeout) during idle. nonce MUST NOT be 1 (the node
 * treats nonce==1 specially: it forces a NodeInfo rebroadcast).
 * Built with nanopb pb_encode.
 *
 * @return 0 on success, -ENOMEM if out_buf is too small, -EINVAL on failure.
 */
int proto_encode_heartbeat(uint32_t nonce, uint8_t *out_buf,
                           uint16_t buf_size, uint16_t *out_len);

/*
 * Encode a synthetic FromRadio{queueStatus} into out_buf (Task D — reactive BLE
 * liveness reply). The node sends a queueStatus in response to a client
 * heartbeat, but it is NOT part of the want_config burst (so it is not cached);
 * the proxy synthesizes a well-formed, benign one (res=0, free/maxlen set,
 * mesh_packet_id=0) so a phone's heartbeat gets the radio-data reply that keeps
 * its liveness timer from tripping. Built with nanopb pb_encode.
 *
 * @return 0 on success, -ENOMEM if out_buf is too small, -EINVAL on failure.
 */
int proto_encode_queue_status(uint8_t *out_buf, uint16_t buf_size,
                              uint16_t *out_len);

#endif /* PROTO_HANDLER_H */
```

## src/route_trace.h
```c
/*
 * route_trace.h — compile-time-gated ROUTE message-path tracing.
 *
 * The ROUTE_* macros expand to Zephyr LOG_INF / LOG_HEXDUMP_INF only when
 * CONFIG_MESHTASTIC_ROUTE_TRACE is set; otherwise they compile to nothing, so
 * the per-packet tracing adds zero processing time on the hot path (arguments
 * are not evaluated when the trace is off). Payload hexdumps are further gated
 * behind CONFIG_MESHTASTIC_ROUTE_TRACE_PAYLOAD.
 *
 * Each translation unit that uses these must have registered its own log module
 * (LOG_MODULE_REGISTER) — the macros emit under that module, exactly like a
 * direct LOG_INF call would.
 */
#ifndef ROUTE_TRACE_H
#define ROUTE_TRACE_H

#include <zephyr/logging/log.h>
#include <zephyr/sys/util.h>   /* IS_ENABLED */

#if IS_ENABLED(CONFIG_MESHTASTIC_ROUTE_TRACE)
#define ROUTE_TRACE(...)  LOG_INF(__VA_ARGS__)
#else
#define ROUTE_TRACE(...)  ((void)0)
#endif

#if IS_ENABLED(CONFIG_MESHTASTIC_ROUTE_TRACE) && \
    IS_ENABLED(CONFIG_MESHTASTIC_ROUTE_TRACE_PAYLOAD)
#define ROUTE_TRACE_HEXDUMP(_data, _len, _label)  LOG_HEXDUMP_INF(_data, _len, _label)
#else
#define ROUTE_TRACE_HEXDUMP(_data, _len, _label)  ((void)0)
#endif

#endif /* ROUTE_TRACE_H */
```

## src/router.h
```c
#ifndef ROUTER_H
#define ROUTER_H

#include <stdint.h>
#include "proto_handler.h"

/*
 * Dispatch a raw FromRadio payload to the appropriate BLE connection(s).
 *
 * Routing rules (in priority order):
 *
 *  1. Non-packet variants (NodeInfo, MyInfo, Channel, Config, ConfigComplete…)
 *     → broadcast to all connections.
 *     Rationale: every phone needs the full config handshake to complete.
 *
 *  2. Encrypted packets (MeshPacket.which_payload_variant != decoded_tag)
 *     → broadcast to all connections (payload cannot be inspected).
 *
 *  3. Decoded packet with portnum == PROXY_PORTNUM (256):
 *     Parse the proxy header from Data.payload.bytes.
 *     Route the raw FromRadio bytes to the BLE connection whose registered
 *     proxy_id matches DST_ID in the header.
 *     Fallback to broadcast if the header is malformed or no connection has
 *     registered that DST_ID yet (guarantees no silent drops).
 *
 *  4. Decoded packet with any other portnum (TEXT_MESSAGE, POSITION, etc.)
 *     → broadcast to all connections.
 *     The phone app filters what it cares about.
 *
 * @param raw_bytes  Protobuf bytes as received from UART (no framing header).
 * @param len        Byte count.
 * @param info       Pre-decoded routing fields from proto_decode_fromradio().
 */
void router_dispatch(const uint8_t *raw_bytes, uint16_t len,
                     const struct fromradio_info *info);

#endif /* ROUTER_H */
```
